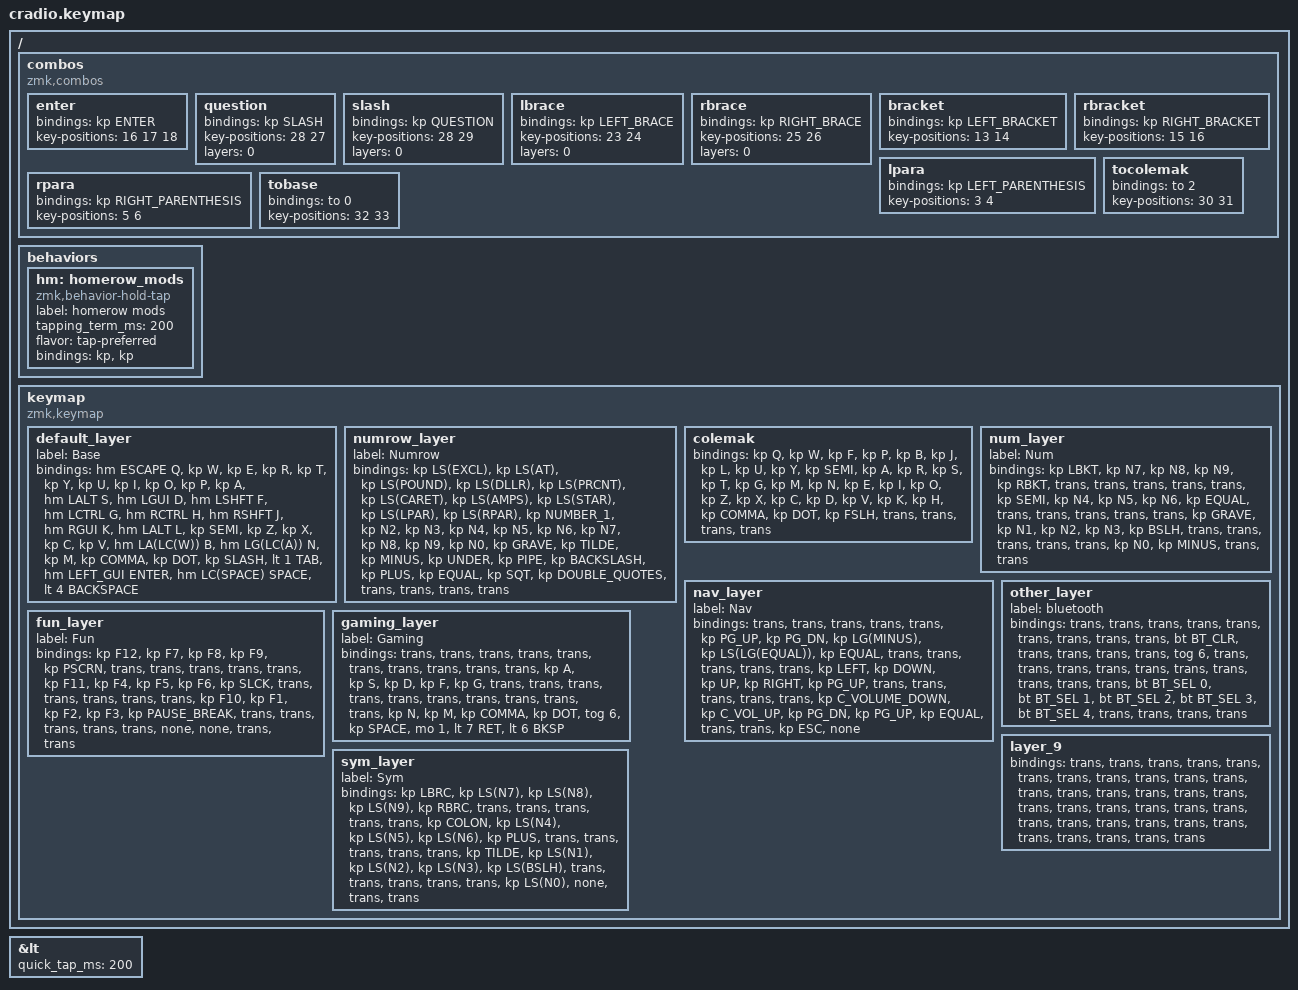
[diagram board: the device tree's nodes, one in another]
/*
 * Copyright (c) 2021 Pete Johanson, modified by Dionysus
 *
 * SPDX-License-Identifier: MIT
 */

#include <behaviors.dtsi>
#include <dt-bindings/zmk/bt.h>
#include <dt-bindings/zmk/keys.h>

#define BSE_L 0
#define NAV_L 1
#define OTH_L 2
#define NUM_L 3
#define SYM_L 4
#define FUN_L 5
#define GME_L 6
#define NMR_L 7

// Using layer taps on thumbs, having quick tap as well helps w/ repeating space/backspace

&lt { quick_tap_ms = <200>; };

/ {
    combos {
        compatible = "zmk,combos";

        enter {
            bindings = <&kp ENTER>;
            key-positions = <16 17 18>;
        };

        question {
            bindings = <&kp SLASH>;
            key-positions = <28 27>;
            layers = <0>;
        };

        slash {
            bindings = <&kp QUESTION>;
            key-positions = <28 29>;
            layers = <0>;
        };

        lbrace {
            bindings = <&kp LEFT_BRACE>;
            key-positions = <23 24>;
            layers = <0>;
        };

        rbrace {
            bindings = <&kp RIGHT_BRACE>;
            key-positions = <25 26>;
            layers = <0>;
        };

        bracket {
            bindings = <&kp LEFT_BRACKET>;
            key-positions = <13 14>;
        };

        rbracket {
            bindings = <&kp RIGHT_BRACKET>;
            key-positions = <15 16>;
        };

        lpara {
            bindings = <&kp LEFT_PARENTHESIS>;
            key-positions = <3 4>;
        };

        rpara {
            bindings = <&kp RIGHT_PARENTHESIS>;
            key-positions = <5 6>;
        };

        tocolemak {
            bindings = <&to 2>;
            key-positions = <30 31>;
        };

        tobase {
            bindings = <&to 0>;
            key-positions = <32 33>;
        };

        /*
        caps_word_combo {
	    timeout-ms = <50>;
            key-positions = <13 16>;
            bindings = <&caps_word>;
        };
	*/
    };

    behaviors {
        hm: homerow_mods {
            compatible = "zmk,behavior-hold-tap";
            label = "homerow mods";
            #binding-cells = <2>;
            tapping_term_ms = <200>;
            flavor = "tap-preferred";
            bindings = <&kp>, <&kp>;
        };
    };

    keymap {
        compatible = "zmk,keymap";

        default_layer {
            label = "Base";
            bindings = <
&hm ESCAPE Q  &kp W  &kp E  &kp R  &kp T  &kp Y  &kp U  &kp I  &kp O  &kp P  &kp A  &hm LALT S  &hm LGUI D  &hm LSHFT F  &hm LCTRL G  &hm RCTRL H  &hm RSHFT J  &hm RGUI K  &hm LALT L  &kp SEMI  &kp Z  &kp X  &kp C  &kp V  &hm LA(LC(W)) B  &hm LG(LC(A)) N  &kp M  &kp COMMA  &kp DOT  &kp SLASH  &lt 1 TAB  &hm LEFT_GUI ENTER  &hm LC(SPACE) SPACE  &lt 4 BACKSPACE
            >;
        };

        numrow_layer {
            label = "Numrow";
            bindings = <
&kp LS(EXCL)  &kp LS(AT)  &kp LS(POUND)  &kp LS(DLLR)  &kp LS(PRCNT)  &kp LS(CARET)  &kp LS(AMPS)  &kp LS(STAR)  &kp LS(LPAR)  &kp LS(RPAR)  &kp NUMBER_1  &kp N2  &kp N3  &kp N4  &kp N5  &kp N6  &kp N7  &kp N8  &kp N9  &kp N0  &kp GRAVE  &kp TILDE  &kp MINUS  &kp UNDER  &kp PIPE  &kp BACKSLASH  &kp PLUS  &kp EQUAL  &kp SQT  &kp DOUBLE_QUOTES  &trans  &trans  &trans  &trans
            >;
        };

        colemak {
            bindings = <
&kp Q  &kp W  &kp F  &kp P  &kp B  &kp J  &kp L  &kp U  &kp Y  &kp SEMI  &kp A  &kp R  &kp S  &kp T  &kp G  &kp M  &kp N  &kp E  &kp I  &kp O  &kp Z  &kp X  &kp C  &kp D  &kp V  &kp K  &kp H  &kp COMMA  &kp DOT  &kp FSLH  &trans  &trans  &trans  &trans
            >;
        };

        num_layer {
            label = "Num";
            bindings = <
&kp LBKT  &kp N7  &kp N8  &kp N9  &kp RBKT  &trans  &trans  &trans  &trans  &trans  &kp SEMI  &kp N4  &kp N5  &kp N6  &kp EQUAL  &trans  &trans  &trans  &trans  &trans  &kp GRAVE  &kp N1  &kp N2  &kp N3  &kp BSLH  &trans  &trans  &trans  &trans  &trans  &kp N0  &kp MINUS  &trans  &trans
            >;
        };

        nav_layer {
            label = "Nav";
            bindings = <
&trans  &trans  &trans  &trans  &trans  &kp PG_UP  &kp PG_DN  &kp LG(MINUS)  &kp LS(LG(EQUAL))  &kp EQUAL  &trans  &trans  &trans  &trans  &trans  &kp LEFT  &kp DOWN  &kp UP  &kp RIGHT  &kp PG_UP  &trans  &trans  &trans  &trans  &trans  &kp C_VOLUME_DOWN  &kp C_VOL_UP  &kp PG_DN  &kp PG_UP  &kp EQUAL  &trans  &trans  &kp ESC  &none
            >;
        };

        fun_layer {
            label = "Fun";
            bindings = <
&kp F12  &kp F7  &kp F8  &kp F9  &kp PSCRN  &trans  &trans  &trans  &trans  &trans  &kp F11  &kp F4  &kp F5  &kp F6  &kp SLCK  &trans  &trans  &trans  &trans  &trans  &kp F10  &kp F1  &kp F2  &kp F3  &kp PAUSE_BREAK  &trans  &trans  &trans  &trans  &trans  &none  &none  &trans  &trans
            >;
        };

        gaming_layer {
            label = "Gaming";
            bindings = <
&trans  &trans  &trans  &trans  &trans  &trans  &trans  &trans  &trans  &trans  &kp A  &kp S  &kp D  &kp F  &kp G  &trans  &trans  &trans  &trans  &trans  &trans  &trans  &trans  &trans  &trans  &kp N  &kp M  &kp COMMA  &kp DOT  &tog 6  &kp SPACE  &mo 1  &lt 7 RET  &lt 6 BKSP
            >;
        };

        other_layer {
            label = "bluetooth";
            bindings = <
&trans  &trans  &trans  &trans  &trans  &trans  &trans  &trans  &trans  &bt BT_CLR  &trans  &trans  &trans  &trans  &tog 6  &trans  &trans  &trans  &trans  &trans  &trans  &trans  &trans  &trans  &trans  &bt BT_SEL 0  &bt BT_SEL 1  &bt BT_SEL 2  &bt BT_SEL 3  &bt BT_SEL 4  &trans  &trans  &trans  &trans
            >;
        };

        sym_layer {
            label = "Sym";
            bindings = <
&kp LBRC  &kp LS(N7)  &kp LS(N8)  &kp LS(N9)  &kp RBRC  &trans  &trans  &trans  &trans  &trans  &kp COLON  &kp LS(N4)  &kp LS(N5)  &kp LS(N6)  &kp PLUS  &trans  &trans  &trans  &trans  &trans  &kp TILDE  &kp LS(N1)  &kp LS(N2)  &kp LS(N3)  &kp LS(BSLH)  &trans  &trans  &trans  &trans  &trans  &kp LS(N0)  &none  &trans  &trans
            >;
        };

        layer_9 {
            bindings = <
&trans  &trans  &trans  &trans  &trans  &trans  &trans  &trans  &trans  &trans  &trans  &trans  &trans  &trans  &trans  &trans  &trans  &trans  &trans  &trans  &trans  &trans  &trans  &trans  &trans  &trans  &trans  &trans  &trans  &trans  &trans  &trans  &trans  &trans
            >;
        };
    };
};
